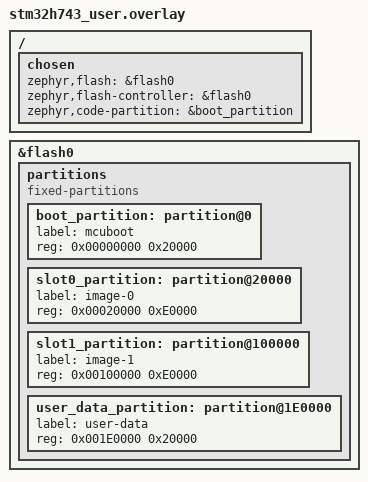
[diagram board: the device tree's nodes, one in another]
/*
 * Copyright (c) 2024 WeAct Studio
 *
 * SPDX-License-Identifier: Apache-2.0
 *
 * MCUboot自身分区配置，与应用的 boards/stm32h743_user.overlay 保持一致
 * MCUboot 放在 boot_partition (0x00000000, 128KB)
 */

/ {
    chosen {
        zephyr,flash = &flash0;
        zephyr,flash-controller = &flash0;
        zephyr,code-partition = &boot_partition;
    };
};

&flash0 {
    ranges;
    partitions {
        compatible = "fixed-partitions";
        #address-cells = <1>;
        #size-cells = <1>;

        boot_partition: partition@0 {
            label = "mcuboot";
            reg = <0x00000000 0x20000>;
        };

        slot0_partition: partition@20000 {
            label = "image-0";
            reg = <0x00020000 0xE0000>;
        };

        slot1_partition: partition@100000 {
            label = "image-1";
            reg = <0x00100000 0xE0000>;
        };

        user_data_partition: partition@1E0000 {
            label = "user-data";
            reg = <0x001E0000 0x20000>;
        };
    };
};
